AUTOSAR XML (schema 00046)
package /ComponentTypes
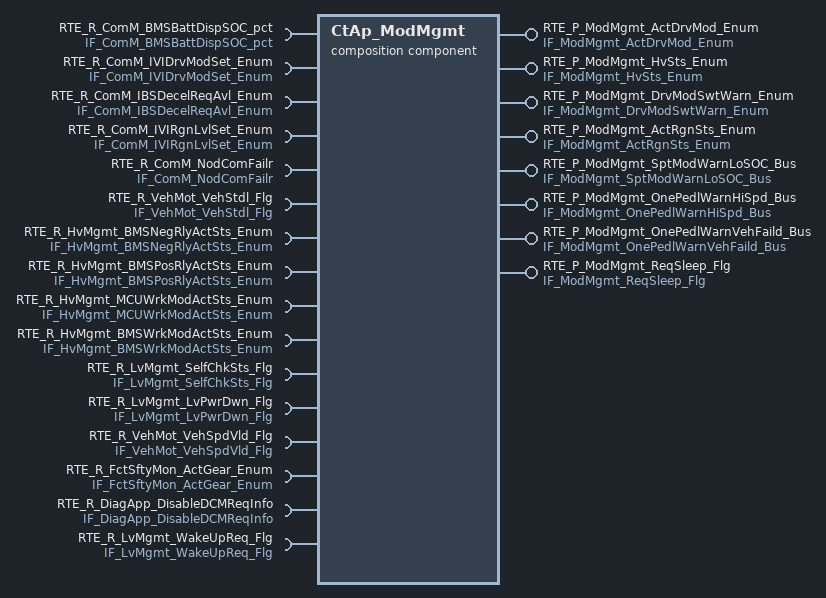
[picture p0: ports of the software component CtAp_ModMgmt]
  composition sw component type CtAp_ModMgmt
    7 x provide port:
      RTE_P_ModMgmt_ActDrvMod_Enum: nonqueued-sender-com-spec{data-element=tec_ModMgmt_ActDrvMod_Enum, init-value=0}, provided-interface=IF_ModMgmt_ActDrvMod_Enum
      RTE_P_ModMgmt_HvSts_Enum: nonqueued-sender-com-spec{data-element=tec_ModMgmt_HvSts_Enum, init-value=0}, provided-interface=IF_ModMgmt_HvSts_Enum
      RTE_P_ModMgmt_DrvModSwtWarn_Enum: nonqueued-sender-com-spec{data-element=tec_ModMgmt_DrvModSwtWarn_Enum, init-value=0}, provided-interface=IF_ModMgmt_DrvModSwtWarn_Enum
      RTE_P_ModMgmt_ActRgnSts_Enum: nonqueued-sender-com-spec{data-element=tec_ModMgmt_ActRgnSts_Enum, init-value=0}, provided-interface=IF_ModMgmt_ActRgnSts_Enum
      RTE_P_ModMgmt_SptModWarnLoSOC_Bus: nonqueued-sender-com-spec{data-element=tec_ModMgmt_SptModWarnLoSOC_Bus, init-value=fields=[ModMgmt_MonStatSptModWarnLoSOC:0, ModMgmt_MonResSptModWarnLoSOC:0, ModMgmt_ErrStatSptModWarnLoSOC:0, ModMgmt_ErrResSptModWarnLoSOC:0]}, provided-interface=IF_ModMgmt_SptModWarnLoSOC_Bus
      RTE_P_ModMgmt_OnePedlWarnHiSpd_Bus: nonqueued-sender-com-spec{data-element=tec_ModMgmt_OnePedlWarnHiSpd_Bus, init-value=fields=[ModMgmt_MonStatOnePedlWarnHiSpd:0, ModMgmt_MonResOnePedlWarnHiSpd:0, ModMgmt_ErrStatOnePedlWarnHiSpd:0, ModMgmt_ErrResOnePedlWarnHiSpd:0]}, provided-interface=IF_ModMgmt_OnePedlWarnHiSpd_Bus
      RTE_P_ModMgmt_OnePedlWarnVehFaild_Bus: nonqueued-sender-com-spec{data-element=tec_ModMgmt_OnePedlWarnVehFaild_Bus, init-value=fields=[ModMgmt_MonStatOnePedlWarnVehFaild:0, ModMgmt_MonResOnePedlWarnVehFaild:0, ModMgmt_ErrStatOnePedlWarnVehFaild:0, ModMgmt_ErrResOnePedlWarnVehFaild:0]}, provided-interface=IF_ModMgmt_OnePedlWarnVehFaild_Bus
    13 x require port:
      RTE_R_ComM_BMSBattDispSOC_pct: nonqueued-receiver-com-spec{data-element=tec_ComM_BMSBattDispSOC_pct, filter=data-filter-type=ALWAYS, init-value=0}, required-interface=IF_ComM_BMSBattDispSOC_pct
      RTE_R_ComM_IVIDrvModSet_Enum: nonqueued-receiver-com-spec{data-element=tec_ComM_IVIDrvModSet_Enum, filter=data-filter-type=ALWAYS, init-value=0}, required-interface=IF_ComM_IVIDrvModSet_Enum
      RTE_R_ComM_IBSDecelReqAvl_Enum: nonqueued-receiver-com-spec{data-element=tec_ComM_IBSDecelReqAvl_Enum, filter=data-filter-type=ALWAYS, init-value=0}, required-interface=IF_ComM_IBSDecelReqAvl_Enum
      RTE_R_ComM_IVIRgnLvlSet_Enum: nonqueued-receiver-com-spec{data-element=tec_ComM_IVIRgnLvlSet_Enum, filter=data-filter-type=ALWAYS, init-value=0}, required-interface=IF_ComM_IVIRgnLvlSet_Enum
      RTE_R_ComM_NodComFailr: required-interface=IF_ComM_NodComFailr
        required-com-specs:
          data-element=tec_ComM_SGWNodComFailr_Flg, filter=data-filter-type=ALWAYS, init-value=0
          data-element=tec_ComM_CGWNodComFailr_Flg, filter=data-filter-type=ALWAYS, init-value=0
          data-element=tec_ComM_TCUNodComFailr_Flg, filter=data-filter-type=ALWAYS, init-value=0
          data-element=tec_ComM_BCMNodComFailr_Flg, filter=data-filter-type=ALWAYS, init-value=0
          data-element=tec_ComM_PRNDNodComFailr_Flg, filter=data-filter-type=ALWAYS, init-value=0
          data-element=tec_ComM_IVINodComFailr_Flg, filter=data-filter-type=ALWAYS, init-value=0
          data-element=tec_ComM_DCDCNodComFailr_Flg, filter=data-filter-type=ALWAYS, init-value=0
          data-element=tec_ComM_OBCNodComFailr_Flg, filter=data-filter-type=ALWAYS, init-value=0
          data-element=tec_ComM_CHIBSNodComFailr_Flg, filter=data-filter-type=ALWAYS, init-value=0
          data-element=tec_ComM_MCUNodComFailr_Flg, filter=data-filter-type=ALWAYS, init-value=0
          data-element=tec_ComM_EVCOMNodComFailr_Flg, filter=data-filter-type=ALWAYS, init-value=0
          data-element=tec_ComM_EPTIBSNodComFailr_Flg, filter=data-filter-type=ALWAYS, init-value=0
          data-element=tec_ComM_DCMNodComFailr_Flg, filter=data-filter-type=ALWAYS, init-value=0
          data-element=tec_ComM_BMSNodComFailr_Flg, filter=data-filter-type=ALWAYS, init-value=0
          data-element=tec_ComM_ACUNodComFailr_Flg, filter=data-filter-type=ALWAYS, init-value=0
          data-element=tec_ComM_APTCNodComFailr_Flg, filter=data-filter-type=ALWAYS, init-value=0
          data-element=tec_ComM_ADCUNodComFailr_Flg, filter=data-filter-type=ALWAYS, init-value=0
          data-element=tec_ComM_DCMRRNodComFailr_Flg, filter=data-filter-type=ALWAYS, init-value=0
          data-element=tec_ComM_DCMRLNodComFailr_Flg, filter=data-filter-type=ALWAYS, init-value=0
          data-element=tec_ComM_DCMFRNodComFailr_Flg, filter=data-filter-type=ALWAYS, init-value=0
          data-element=tec_ComM_DCMFLNodComFailr_Flg, filter=data-filter-type=ALWAYS, init-value=0
          data-element=tec_ComM_SGWCHNodComFailr_Flg, filter=data-filter-type=ALWAYS, init-value=0
      RTE_R_VehMot_VehStdl_Flg: nonqueued-receiver-com-spec{data-element=tec_VehMot_VehStdl_Flg, filter=data-filter-type=ALWAYS, init-value=0}, required-interface=IF_VehMot_VehStdl_Flg
      RTE_R_HvMgmt_BMSNegRlyActSts_Enum: nonqueued-receiver-com-spec{data-element=tec_HvMgmt_BMSNegRlyActSts_Enum, filter=data-filter-type=ALWAYS, init-value=0}, required-interface=IF_HvMgmt_BMSNegRlyActSts_Enum
      RTE_R_HvMgmt_BMSPosRlyActSts_Enum: nonqueued-receiver-com-spec{data-element=tec_HvMgmt_BMSPosRlyActSts_Enum, filter=data-filter-type=ALWAYS, init-value=0}, required-interface=IF_HvMgmt_BMSPosRlyActSts_Enum
      RTE_R_HvMgmt_MCUWrkModActSts_Enum: nonqueued-receiver-com-spec{data-element=tec_HvMgmt_MCUWrkModActSts_Enum, filter=data-filter-type=ALWAYS, init-value=0}, required-interface=IF_HvMgmt_MCUWrkModActSts_Enum
      RTE_R_HvMgmt_BMSWrkModActSts_Enum: nonqueued-receiver-com-spec{data-element=tec_HvMgmt_BMSWrkModActSts_Enum, filter=data-filter-type=ALWAYS, init-value=0}, required-interface=IF_HvMgmt_BMSWrkModActSts_Enum
      RTE_R_LvMgmt_SelfChkSts_Flg: nonqueued-receiver-com-spec{data-element=tec_LvMgmt_SelfChkSts_Flg, filter=data-filter-type=ALWAYS, init-value=0}, required-interface=IF_LvMgmt_SelfChkSts_Flg
      RTE_R_LvMgmt_LvPwrDwn_Flg: nonqueued-receiver-com-spec{data-element=tec_LvMgmt_LvPwrDwn_Flg, filter=data-filter-type=ALWAYS, init-value=0}, required-interface=IF_LvMgmt_LvPwrDwn_Flg
      RTE_R_VehMot_VehSpdVld_Flg: nonqueued-receiver-com-spec{data-element=tec_VehMot_VehSpdVld_Flg, filter=data-filter-type=ALWAYS, init-value=0}, required-interface=IF_VehMot_VehSpdVld_Flg
    provide port RTE_P_ModMgmt_ReqSleep_Flg: nonqueued-sender-com-spec{data-element=tec_ModMgmt_ReqSleep_Flg, init-value=0}, provided-interface=IF_ModMgmt_ReqSleep_Flg
    provide/require port RTE_RP_ModMgmtInfo:
      nv-provide-com-spec{ram-block-init-value=fields=[ModMgmt_DrvModMemInfo_Enum:2, ModMgmt_ActRgnStsMemInfo_Enum:3], rom-block-init-value=fields=[ModMgmt_DrvModMemInfo_Enum:2, ModMgmt_ActRgnStsMemInfo_Enum:3], variable=tec_ModMgmtInfo}
      nv-require-com-spec{init-value=fields=[ModMgmt_DrvModMemInfo_Enum:2, ModMgmt_ActRgnStsMemInfo_Enum:3], variable=tec_ModMgmtInfo}
      provided-required-interface=IF_ModMgmtInfo
    require port RTE_R_FctSftyMon_ActGear_Enum: nonqueued-receiver-com-spec{data-element=tec_FctSftyMon_ActGear_Enum, filter=data-filter-type=ALWAYS}, required-interface=IF_FctSftyMon_ActGear_Enum
    require port RTE_R_DiagApp_DisableDCMReqInfo: nonqueued-receiver-com-spec{data-element=tec_DiagApp_DisableDCMReqInfo, filter=data-filter-type=ALWAYS, init-value=0}, required-interface=IF_DiagApp_DisableDCMReqInfo
    require port RTE_R_LvMgmt_WakeUpReq_Flg: nonqueued-receiver-com-spec{data-element=tec_LvMgmt_WakeUpReq_Flg, filter=data-filter-type=ALWAYS, init-value=0}, required-interface=IF_LvMgmt_WakeUpReq_Flg
    component CtAp_DrvMod: type=CtAp_DrvMod
    component CtAp_VehStat: type=CtAp_VehStat
    delegate CtAp_DrvMod.RTE_R_ComM_IBSDecelReqAvl_Enum <-> outer port RTE_R_ComM_IBSDecelReqAvl_Enum
    delegate CtAp_DrvMod.RTE_R_ComM_IVIDrvModSet_Enum <-> outer port RTE_R_ComM_IVIDrvModSet_Enum
    delegate CtAp_DrvMod.RTE_R_ComM_IVIRgnLvlSet_Enum <-> outer port RTE_R_ComM_IVIRgnLvlSet_Enum
    delegate CtAp_DrvMod.RTE_R_ComM_BMSBattDispSOC_pct <-> outer port RTE_R_ComM_BMSBattDispSOC_pct
    delegate CtAp_DrvMod.RTE_R_ComM_NodComFailr <-> outer port RTE_R_ComM_NodComFailr
    delegate CtAp_DrvMod.RTE_P_ModMgmt_DrvModSwtWarn_Enum <-> outer port RTE_P_ModMgmt_DrvModSwtWarn_Enum
    delegate CtAp_DrvMod.RTE_P_ModMgmt_ActRgnSts_Enum <-> outer port RTE_P_ModMgmt_ActRgnSts_Enum
    delegate CtAp_DrvMod.RTE_P_ModMgmt_OnePedlWarnHiSpd_Bus <-> outer port RTE_P_ModMgmt_OnePedlWarnHiSpd_Bus
    delegate CtAp_DrvMod.RTE_P_ModMgmt_OnePedlWarnVehFaild_Bus <-> outer port RTE_P_ModMgmt_OnePedlWarnVehFaild_Bus
    delegate CtAp_DrvMod.RTE_P_ModMgmt_SptModWarnLoSOC_Bus <-> outer port RTE_P_ModMgmt_SptModWarnLoSOC_Bus
    delegate CtAp_DrvMod.RTE_P_ModMgmt_ActDrvMod_Enum <-> outer port RTE_P_ModMgmt_ActDrvMod_Enum
    delegate CtAp_VehStat.RTE_P_ModMgmt_ReqSleep_Flg <-> outer port RTE_P_ModMgmt_ReqSleep_Flg
    delegate CtAp_VehStat.RTE_P_ModMgmt_HvSts_Enum <-> outer port RTE_P_ModMgmt_HvSts_Enum
    connect CtAp_VehStat.RTE_P_ModMgmt_HvSts_Enum -> CtAp_DrvMod.RTE_R_ModMgmt_HvSts_Enum
    delegate CtAp_VehStat.RTE_R_VehMot_VehSpdVld_Flg <-> outer port RTE_R_VehMot_VehSpdVld_Flg
    delegate CtAp_VehStat.RTE_R_LvMgmt_LvPwrDwn_Flg <-> outer port RTE_R_LvMgmt_LvPwrDwn_Flg
    delegate CtAp_VehStat.RTE_R_LvMgmt_SelfChkSts_Flg <-> outer port RTE_R_LvMgmt_SelfChkSts_Flg
    delegate CtAp_VehStat.RTE_R_HvMgmt_BMSNegRlyActSts_Enum <-> outer port RTE_R_HvMgmt_BMSNegRlyActSts_Enum
    delegate CtAp_VehStat.RTE_R_HvMgmt_BMSWrkModActSts_Enum <-> outer port RTE_R_HvMgmt_BMSWrkModActSts_Enum
    delegate CtAp_VehStat.RTE_R_HvMgmt_MCUWrkModActSts_Enum <-> outer port RTE_R_HvMgmt_MCUWrkModActSts_Enum
    delegate CtAp_VehStat.RTE_R_HvMgmt_BMSPosRlyActSts_Enum <-> outer port RTE_R_HvMgmt_BMSPosRlyActSts_Enum
    delegate CtAp_VehStat.RTE_R_VehMot_VehStdl_Flg <-> outer port RTE_R_VehMot_VehStdl_Flg
    delegate CtAp_DrvMod.RTE_RP_ModMgmtInfo <-> outer port RTE_RP_ModMgmtInfo
    delegate CtAp_DrvMod.RTE_R_FctSftyMon_ActGear_Enum <-> outer port RTE_R_FctSftyMon_ActGear_Enum
    delegate CtAp_DrvMod.RTE_R_DiagApp_DisableDCMReqInfo <-> outer port RTE_R_DiagApp_DisableDCMReqInfo
    delegate CtAp_VehStat.RTE_R_LvMgmt_WakeUpReq_Flg <-> outer port RTE_R_LvMgmt_WakeUpReq_Flg
